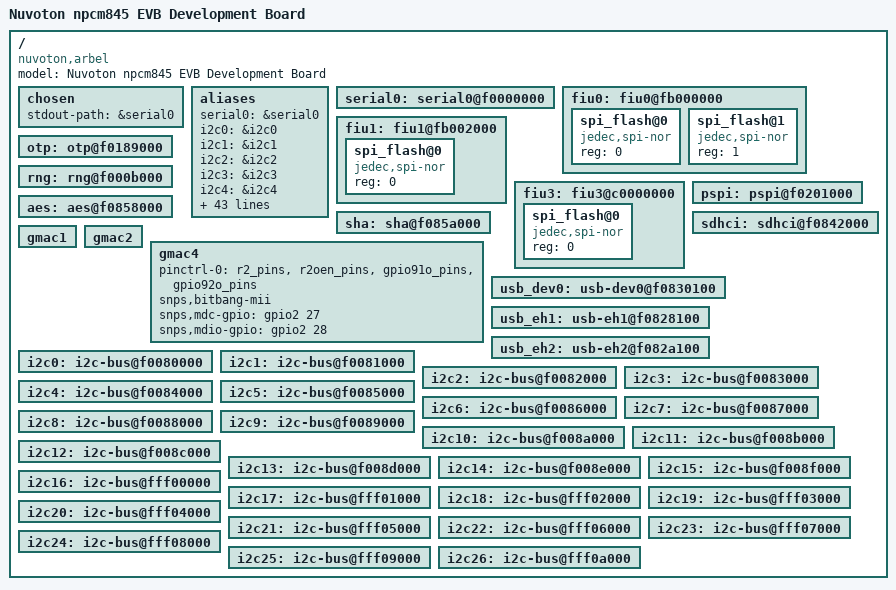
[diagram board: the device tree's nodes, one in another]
// SPDX-License-Identifier: GPL-2.0+

/dts-v1/;
#include "nuvoton-common-npcm8xx.dtsi"
#include "nuvoton-npcm845-pincfg.dtsi"

/ {
	model = "Nuvoton npcm845 EVB Development Board";
	compatible = "nuvoton,arbel", "nuvoton,npcm845";

	chosen {
		stdout-path = &serial0;
	};

	aliases {
		serial0 = &serial0;
		i2c0 = &i2c0;
		i2c1 = &i2c1;
		i2c2 = &i2c2;
		i2c3 = &i2c3;
		i2c4 = &i2c4;
		i2c5 = &i2c5;
		i2c6 = &i2c6;
		i2c7 = &i2c7;
		i2c8 = &i2c8;
		i2c9 = &i2c9;
		i2c10 = &i2c10;
		i2c11 = &i2c11;
		i2c12 = &i2c12;
		i2c13 = &i2c13;
		i2c14 = &i2c14;
		i2c15 = &i2c15;
		i2c16 = &i2c16;
		i2c17 = &i2c17;
		i2c18 = &i2c18;
		i2c19 = &i2c19;
		i2c20 = &i2c20;
		i2c21 = &i2c21;
		i2c22 = &i2c22;
		i2c23 = &i2c23;
		i2c24 = &i2c24;
		i2c25 = &i2c25;
		i2c26 = &i2c26;
		spi0 = &fiu0;
		spi1 = &fiu1;
		spi3 = &fiu3;
		spi4 = &fiux;
		spi5 = &pspi;
		mmc0 = &sdhci;
		gpio0 = &gpio0;
		gpio1 = &gpio1;
		gpio2 = &gpio2;
		gpio3 = &gpio3;
		gpio4 = &gpio4;
		gpio5 = &gpio5;
		gpio6 = &gpio6;
		gpio7 = &gpio7;
		usb0 = &usb_dev0;
		usb1 = &usb_eh1;
		usb2 = &usb_eh2;
		eth0 = &gmac1;
		eth1 = &gmac2;
		eth2 = &gmac3;
		eth3 = &gmac4;
	};

	serial0: serial0@f0000000 {
		status = "okay";
	};

	fiu0: fiu0@fb000000 {
		status = "okay";
		spi_flash@0 {
			compatible = "jedec,spi-nor";
			reg = <0>; /* CS 0 */
		};

		spi_flash@1 {
			compatible = "jedec,spi-nor";
			reg = <1>;  /* CS 1 */
		};
	};

	fiu1: fiu1@fb002000 {
		status = "okay";
		spi_flash@0 {
			compatible = "jedec,spi-nor";
			reg = <0>; /* CS 0 */
		};
	};

	fiu3: fiu3@c0000000 {
		status = "okay";
		spi_flash@0 {
			compatible = "jedec,spi-nor";
			reg = <0>; /* CS 0 */
		};
	};

	pspi: pspi@f0201000 {
		status = "okay";
	};

	sdhci: sdhci@f0842000 {
		status = "okay";
	};

	otp: otp@f0189000 {
		status = "okay";
	};

	rng: rng@f000b000 {
		status = "okay";
	};

	aes: aes@f0858000 {
		status = "okay";
	};

	sha: sha@f085a000 {
		status = "okay";
	};

	gmac1: gmac1 {   /* GMAC1- SGMII */
		status = "okay";
	};

	gmac2: gmac2 {   /* GMAC2- RGMII */
		status = "okay";
	};

	gmac4: gmac4 {   /* GMAC4- RMII2 */
		status = "okay";
		pinctrl-names = "default";
		pinctrl-0 = <&r2_pins
			     &r2oen_pins
			     &gpio91o_pins
			     &gpio92o_pins>;
		snps,bitbang-mii;
		snps,mdc-gpio = <&gpio2 27 GPIO_ACTIVE_HIGH>;    /* gpio91 */
		snps,mdio-gpio = <&gpio2 28 GPIO_ACTIVE_HIGH>;    /* gpio92 */
	};

	usb_dev0: usb-dev0@f0830100 {
		status = "okay";
	};

	usb_eh1: usb-eh1@f0828100 {
		status = "okay";
	};

	usb_eh2: usb-eh2@f082a100 {
		status = "okay";
	};

	i2c0: i2c-bus@f0080000 {
		status = "okay";
	};

	i2c1: i2c-bus@f0081000 {
		status = "okay";
	};

	i2c2: i2c-bus@f0082000 {
		status = "okay";
	};

	i2c3: i2c-bus@f0083000 {
		status = "okay";
	};

	i2c4: i2c-bus@f0084000 {
		status = "okay";
	};

	i2c5: i2c-bus@f0085000 {
		status = "okay";
	};

	i2c6: i2c-bus@f0086000 {
		status = "okay";
	};

	i2c7: i2c-bus@f0087000 {
		status = "okay";
	};

	i2c8: i2c-bus@f0088000 {
		status = "okay";
	};

	i2c9: i2c-bus@f0089000 {
		status = "okay";
	};

	i2c10: i2c-bus@f008a000 {
		status = "okay";
	};

	i2c11: i2c-bus@f008b000 {
		status = "okay";
	};

	i2c12: i2c-bus@f008c000 {
		status = "okay";
	};

	i2c13: i2c-bus@f008d000 {
		status = "okay";
	};

	i2c14: i2c-bus@f008e000 {
		status = "okay";
	};

	i2c15: i2c-bus@f008f000 {
		status = "okay";
	};

	i2c16: i2c-bus@fff00000 {
		status = "okay";
	};

	i2c17: i2c-bus@fff01000 {
		status = "okay";
	};

	i2c18: i2c-bus@fff02000 {
		status = "okay";
	};

	i2c19: i2c-bus@fff03000 {
		status = "okay";
	};

	i2c20: i2c-bus@fff04000 {
		status = "okay";
	};

	i2c21: i2c-bus@fff05000 {
		status = "okay";
	};

	i2c22: i2c-bus@fff06000 {
		status = "okay";
	};

	i2c23: i2c-bus@fff07000 {
		status = "okay";
	};

	i2c24: i2c-bus@fff08000 {
		status = "okay";
	};

	i2c25: i2c-bus@fff09000 {
		status = "okay";
	};

	i2c26: i2c-bus@fff0a000 {
		status = "okay";
	};

};
